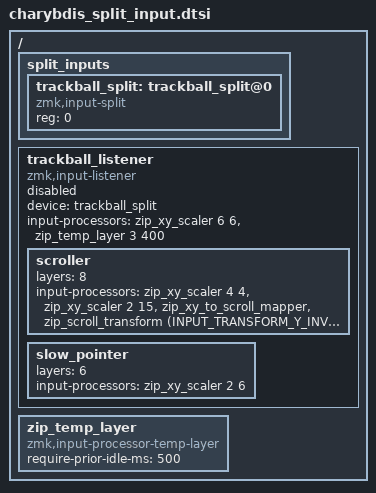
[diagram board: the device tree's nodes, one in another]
// Split input configuration for Charybdis trackball
// This defines the split input infrastructure for receiving trackball data on the central (dongle)
// Based on working Prospector split_input_common.dtsi

#include <dt-bindings/zmk/input_transform.h>
#include <input/processors.dtsi>

/ {
    split_inputs {
        #address-cells = <1>;
        #size-cells = <0>;

        trackball_split: trackball_split@0 {
            compatible = "zmk,input-split";
            reg = <0>;
        };
    };

    trackball_listener: trackball_listener {
        compatible = "zmk,input-listener";
        status = "disabled";
        device = <&trackball_split>;

        /* base processor chain - sensitivity and auto mouse layer */
        input-processors = <&zip_xy_scaler 6 6 &zip_temp_layer 3 400>;

        /* layer-8 scroll override */
        scroller {
            layers = <8>;
            input-processors = <
                &zip_xy_scaler 4 4
                &zip_xy_scaler 2 15
                &zip_xy_to_scroll_mapper
                &zip_scroll_transform (INPUT_TRANSFORM_Y_INVERT)
            >;
        };

        /* layer-6 slow-pointer override */
        slow_pointer {
            layers = <6>;
            input-processors = <&zip_xy_scaler 2 6>;
        };
    };

    zip_temp_layer: zip_temp_layer {
        compatible = "zmk,input-processor-temp-layer";
        #input-processor-cells = <2>;
        require-prior-idle-ms = <500>;
    };
};
